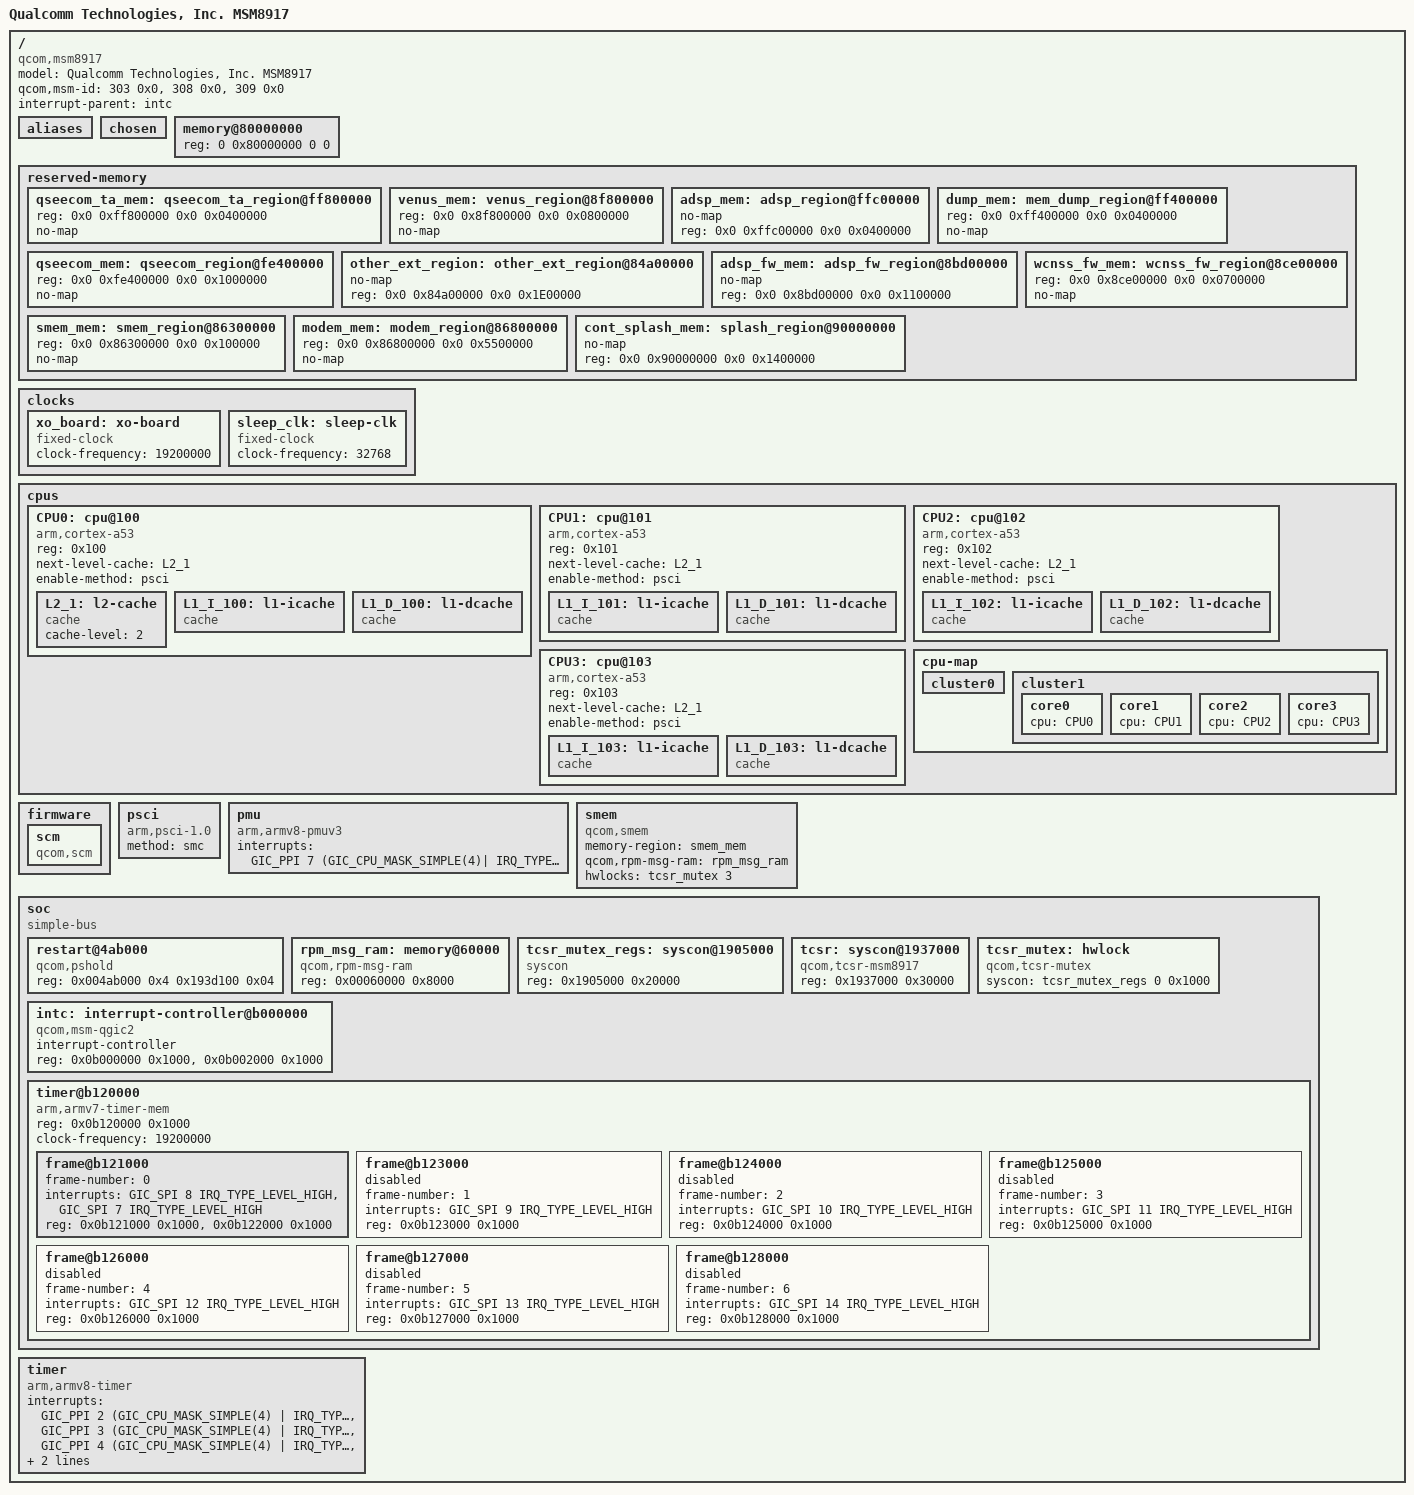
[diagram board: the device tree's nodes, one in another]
// SPDX-License-Identifier: GPL-2.0-only
/*
 * Copyright (c) 2021, Avishek Sen <x0rzavi@gmail.com>
 */

#include <dt-bindings/interrupt-controller/arm-gic.h>

/ {
	model = "Qualcomm Technologies, Inc. MSM8917";
	compatible = "qcom,msm8917";
	qcom,msm-id = <303 0x0>, <308 0x0>, <309 0x0>;
	
	interrupt-parent = <&intc>;

	#address-cells = <2>;
	#size-cells = <2>;

	aliases { };

	chosen { };

	memory@80000000 {
		device_type = "memory";
		/* We expect the bootloader to fill in the reg */
		reg = <0 0x80000000 0 0>;
	};

	reserved-memory {
		#address-cells = <2>;
		#size-cells = <2>;
		ranges;

		qseecom_ta_mem: qseecom_ta_region@ff800000 {
			reg = <0x0 0xff800000 0x0 0x0400000>;
			no-map;
		};

		venus_mem: venus_region@8f800000 {
			reg = <0x0 0x8f800000 0x0 0x0800000>;
			no-map;
		};

		adsp_mem: adsp_region@ffc00000 {
			no-map;
			reg = <0x0 0xffc00000 0x0 0x0400000>;
		};

		dump_mem: mem_dump_region@ff400000 {
			reg = <0x0 0xff400000 0x0 0x0400000>;
			no-map;
		};

		qseecom_mem: qseecom_region@fe400000 {
			reg = <0x0 0xfe400000 0x0 0x1000000>;
			no-map;
		};

		// Check later for msm8917 and ugglite differences
		other_ext_region: other_ext_region@84a00000 {
			no-map;
			reg = <0x0 0x84a00000 0x0 0x1E00000>;
		};

		adsp_fw_mem: adsp_fw_region@8bd00000 {
			no-map;
			reg = <0x0 0x8bd00000 0x0 0x1100000>;
		};

		wcnss_fw_mem: wcnss_fw_region@8ce00000 {
			reg = <0x0 0x8ce00000 0x0 0x0700000>;
			no-map;
		};

		// Check later for existence and need
		smem_mem: smem_region@86300000 {
			reg = <0x0 0x86300000 0x0 0x100000>;
			no-map;
		};

		// Check later for naming
		modem_mem: modem_region@86800000 {
			reg = <0x0 0x86800000 0x0 0x5500000>;
			no-map;
		};

		// Check later for existence and need
		/* rmtfs@00000000 {
			compatible = "qcom,rmtfs-mem";
			reg = <0x0 0x00000000 0x0 0x180000>;
			no-map;

			qcom,client-id = <1>;
		}; */

		cont_splash_mem: splash_region@90000000 {
			no-map;
			reg = <0x0 0x90000000 0x0 0x1400000>;
		};
	};

	clocks {
		xo_board: xo-board {
			compatible = "fixed-clock";
			#clock-cells = <0>;
			clock-frequency = <19200000>;
		};

		sleep_clk: sleep-clk {
			compatible = "fixed-clock";
			#clock-cells = <0>;
			clock-frequency = <32768>;
		};
	};

	cpus {
		#address-cells = <1>;
		#size-cells = <0>;
		
		CPU0: cpu@100 {
			device_type = "cpu";
			compatible = "arm,cortex-a53";
			reg = <0x100>;
			next-level-cache = <&L2_1>;
			enable-method = "psci";
			#cooling-cells = <2>;
			L2_1: l2-cache {
			      compatible = "cache";
			      cache-level = <2>;
			};
			L1_I_100: l1-icache {
				compatible = "cache";
			};
			L1_D_100: l1-dcache {
				compatible = "cache";
			};
		};

		CPU1: cpu@101 {
			device_type = "cpu";
			compatible = "arm,cortex-a53";
			reg = <0x101>;
			next-level-cache = <&L2_1>;
			enable-method = "psci";
			#cooling-cells = <2>;
			L1_I_101: l1-icache {
				compatible = "cache";
			};
			L1_D_101: l1-dcache {
				compatible = "cache";
			};
		};

		CPU2: cpu@102 {
			device_type = "cpu";
			compatible = "arm,cortex-a53";
			reg = <0x102>;
			next-level-cache = <&L2_1>;
			enable-method = "psci";
			#cooling-cells = <2>;
			L1_I_102: l1-icache {
				compatible = "cache";
			};
			L1_D_102: l1-dcache {
				compatible = "cache";
			};
		};

		CPU3: cpu@103 {
			device_type = "cpu";
			compatible = "arm,cortex-a53";
			reg = <0x103>;
			next-level-cache = <&L2_1>;
			enable-method = "psci";
			#cooling-cells = <2>;
			L1_I_103: l1-icache {
				compatible = "cache";
			};
			L1_D_103: l1-dcache {
				compatible = "cache";
			};
		};

		cpu-map {

			cluster0 {
			};

			cluster1 {
				core0 {
					cpu = <&CPU0>;
				};
				core1 {
					cpu = <&CPU1>;
				};
				core2 {
					cpu = <&CPU2>;
				};
				core3 {
					cpu = <&CPU3>;
				};
			};
		};
	};

	// Check later for extension
	firmware {
		scm {
			compatible = "qcom,scm";
		};
	};

	psci {
		compatible = "arm,psci-1.0";
		method = "smc";
	};

	pmu {
		compatible = "arm,armv8-pmuv3";
		interrupts = <GIC_PPI 7 (GIC_CPU_MASK_SIMPLE(4)| IRQ_TYPE_LEVEL_HIGH)>;
	};

	// Check later for existence and need
	smem {
		compatible = "qcom,smem";
		memory-region = <&smem_mem>;
		qcom,rpm-msg-ram = <&rpm_msg_ram>;
		hwlocks = <&tcsr_mutex 3>;
	}; 

	soc: soc {
		#address-cells = <1>;
		#size-cells = <1>;
		ranges = <0 0 0 0xffffffff>;
		compatible = "simple-bus";

		restart@4ab000 {
			compatible = "qcom,pshold";
			reg = <0x004ab000 0x4 0x193d100 0x04>;
		};

		rpm_msg_ram: memory@60000 {
			compatible = "qcom,rpm-msg-ram";
			reg = <0x00060000 0x8000>;
		};

		tcsr_mutex_regs: syscon@1905000 {
			compatible = "syscon";
			reg = <0x1905000 0x20000>;
		};

		tcsr: syscon@1937000 {
			compatible = "qcom,tcsr-msm8917", "syscon";
			reg = <0x1937000 0x30000>;
		};

		tcsr_mutex: hwlock {
			compatible = "qcom,tcsr-mutex";
			syscon = <&tcsr_mutex_regs 0 0x1000>;
			#hwlock-cells = <1>;
		};

		intc: interrupt-controller@b000000 {
			compatible = "qcom,msm-qgic2";
			interrupt-controller;
			#interrupt-cells = <3>;
			reg = <0x0b000000 0x1000>, <0x0b002000 0x1000>;
		};

		timer@b120000 {
			#address-cells = <1>;
			#size-cells = <1>;
			ranges;
			compatible = "arm,armv7-timer-mem";
			reg = <0x0b120000 0x1000>;
			clock-frequency = <19200000>;

			frame@b121000 {
				frame-number = <0>;
				interrupts = <GIC_SPI 8 IRQ_TYPE_LEVEL_HIGH>,
					     <GIC_SPI 7 IRQ_TYPE_LEVEL_HIGH>;
				reg = <0x0b121000 0x1000>,
				      <0x0b122000 0x1000>;
			};

			frame@b123000 {
				frame-number = <1>;
				interrupts = <GIC_SPI 9 IRQ_TYPE_LEVEL_HIGH>;
				reg = <0x0b123000 0x1000>;
				status = "disabled";
			};

			frame@b124000 {
				frame-number = <2>;
				interrupts = <GIC_SPI 10 IRQ_TYPE_LEVEL_HIGH>;
				reg = <0x0b124000 0x1000>;
				status = "disabled";
			};

			frame@b125000 {
				frame-number = <3>;
				interrupts = <GIC_SPI 11 IRQ_TYPE_LEVEL_HIGH>;
				reg = <0x0b125000 0x1000>;
				status = "disabled";
			};

			frame@b126000 {
				frame-number = <4>;
				interrupts = <GIC_SPI 12 IRQ_TYPE_LEVEL_HIGH>;
				reg = <0x0b126000 0x1000>;
				status = "disabled";
			};

			frame@b127000 {
				frame-number = <5>;
				interrupts = <GIC_SPI 13 IRQ_TYPE_LEVEL_HIGH>;
				reg = <0x0b127000 0x1000>;
				status = "disabled";
			};

			frame@b128000 {
				frame-number = <6>;
				interrupts = <GIC_SPI 14 IRQ_TYPE_LEVEL_HIGH>;
				reg = <0x0b128000 0x1000>;
				status = "disabled";
			};
		};
	};

	timer {
		compatible = "arm,armv8-timer";
		interrupts = <GIC_PPI 2 (GIC_CPU_MASK_SIMPLE(4) | IRQ_TYPE_LEVEL_LOW)>,
			     <GIC_PPI 3 (GIC_CPU_MASK_SIMPLE(4) | IRQ_TYPE_LEVEL_LOW)>,
			     <GIC_PPI 4 (GIC_CPU_MASK_SIMPLE(4) | IRQ_TYPE_LEVEL_LOW)>,
			     <GIC_PPI 1 (GIC_CPU_MASK_SIMPLE(4) | IRQ_TYPE_LEVEL_LOW)>;
		clock-frequency = <19200000>;
	};
};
